# LM3S6965 register map
Vendor: Texas Instruments; File version: 1.0
Stellaris LM3S6965, подмножество: SYSCTL, GPIOA–GPIOG, UART0, UART1, TIMER0–TIMER3, ADC0
CPU: CM3 r2p0, little endian, MPU, no FPU, 3 interrupt priority bits
Registers are 32-bit, read-write, reset 0x0 unless marked. A register's access mark holds for its fields unless they carry their own. Offsets are from the block's base; lines under a group give offsets from that group; [hi:lo] are bit positions; {n}, {i} and the like mark numbered series; 'fields as' and 'values as' point back to an identical list; <NAME> marks a mode.

## Memory map
0x40004000 GPIOA size 0x1000 — Порт ввода-вывода общего назначения (PL061)
0x40005000 GPIOB size 0x1000
0x40006000 GPIOC size 0x1000
0x40007000 GPIOD size 0x1000
0x4000C000 UART0 size 0x1000 — Универсальный асинхронный приёмопередатчик (PL011)
0x4000D000 UART1 size 0x1000
0x40024000 GPIOE size 0x1000
0x40025000 GPIOF size 0x1000
0x40026000 GPIOG size 0x1000
0x40030000 TIMER0 size 0x1000 — Таймер общего назначения (GPTM)
0x40031000 TIMER1 size 0x1000
0x40032000 TIMER2 size 0x1000
0x40033000 TIMER3 size 0x1000
0x40038000 ADC0 size 0x1000 — Аналого-цифровой преобразователь, 10 бит
0x400FE000 SYSCTL size 0x1000 — Системное управление: тактирование и сброс

## Interrupts
0 GPIOA
1 GPIOB
2 GPIOC
3 GPIOD
4 GPIOE
5 UART0
6 UART1
14 ADC0SS0 (ADC0)
15 ADC0SS1 (ADC0)
16 ADC0SS2 (ADC0)
17 ADC0SS3 (ADC0)
19 TIMER0A (TIMER0)
20 TIMER0B (TIMER0)
21 TIMER1A (TIMER1)
22 TIMER1B (TIMER1)
23 TIMER2A (TIMER2)
24 TIMER2B (TIMER2)
30 GPIOF
31 GPIOG
35 TIMER3A (TIMER3)
36 TIMER3B (TIMER3)

## SYSCTL — Системное управление: тактирование и сброс
Base 0x400FE000
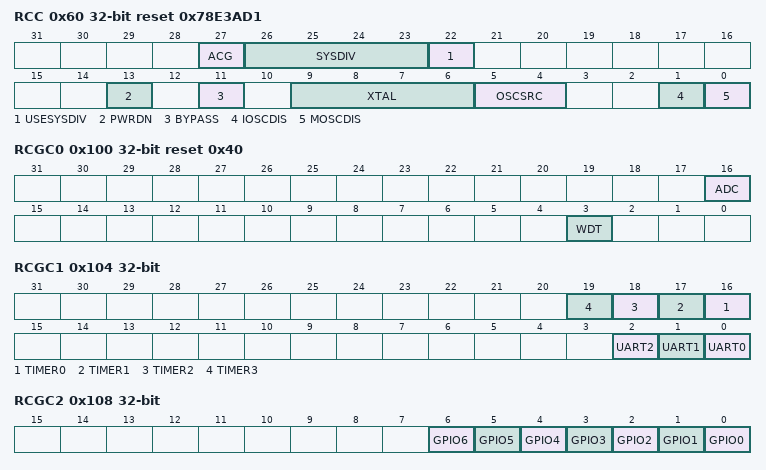
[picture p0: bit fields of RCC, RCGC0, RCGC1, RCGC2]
0x60 RCC reset 0x78E3AD1 — Настройка тактирования
  [27] ACG — Автоматическое управление тактами в режимах сна
  [26:23] SYSDIV — Делитель системной частоты
  [22] USESYSDIV — Делить системную частоту на SYSDIV + 1
  [13] PWRDN — Выключить PLL
  [11] BYPASS — Обойти PLL
  [9:6] XTAL — Частота кварца
  [5:4] OSCSRC — Источник тактов
    0=MAIN (Главный генератор); 1=INTERNAL (Внутренний генератор 12 МГц); 2=INTERNAL_DIV4 (Внутренний генератор, делённый на 4)
  [1] IOSCDIS — Выключить внутренний генератор
  [0] MOSCDIS — Выключить главный генератор
0x100 RCGC0 reset 0x40 — Такты периферии в рабочем режиме, группа 0
  [16] ADC — АЦП
  [3] WDT — Сторожевой таймер
0x104 RCGC1 — Такты периферии в рабочем режиме, группа 1
  [n+16] TIMER{n} (n=0..3) — Таймеры 0–3
  [n] UART{n} (n=0..2) — UART0–UART2
0x108 RCGC2 — Такты периферии в рабочем режиме, группа 2: порты GPIO
  [n] GPIO{n} (n=0..6) — Порты A–G (бит 0 — порт A)

## GPIOA — Порт ввода-вывода общего назначения (PL061)
Base 0x40004000
Same registers: GPIOB 0x40005000, GPIOC 0x40006000, GPIOD 0x40007000, GPIOE 0x40024000, GPIOF 0x40025000, GPIOG 0x40026000
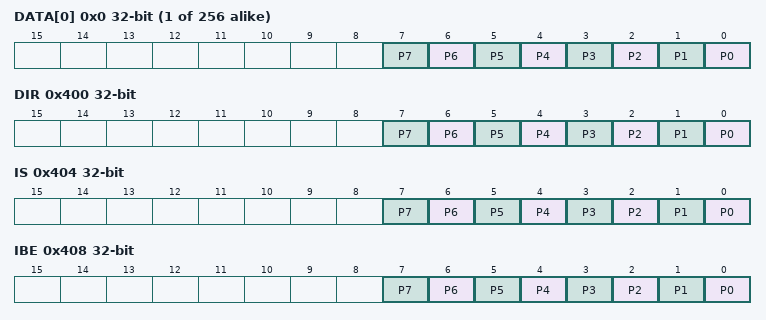
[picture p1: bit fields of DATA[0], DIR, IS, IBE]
{0x0+4i} DATA[{i}] (i=0..255) — Данные. Биты 2–9 адреса — маска: читаются и пишутся только выводы, чьи биты маски равны 1
  [n] P{n} (n=0..7) — Уровень вывода
0x400 DIR — Направление: 1 — выход
  [n] P{n} (n=0..7) — Вывод — выход
0x404 IS — Чувствительность прерывания: 1 — по уровню, 0 — по фронту
  [n] P{n} (n=0..7) — По уровню
0x408 IBE — Прерывание по обоим фронтам
  [n] P{n} (n=0..7) — Оба фронта
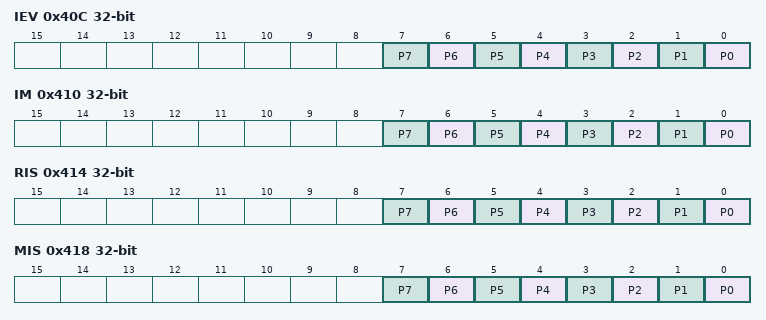
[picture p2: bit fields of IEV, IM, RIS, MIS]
0x40C IEV — Событие прерывания: 1 — нарастающий фронт или высокий уровень
  [n] P{n} (n=0..7) — Нарастающий фронт или высокий уровень
0x410 IM — Маска прерываний: 1 — прерывание разрешено
  [n] P{n} (n=0..7) — Прерывание разрешено
0x414 RIS ro — Необработанные запросы прерываний
  [n] P{n} (n=0..7) — Запрос есть
0x418 MIS ro — Запросы прерываний после маски
  [n] P{n} (n=0..7) — Запрос есть
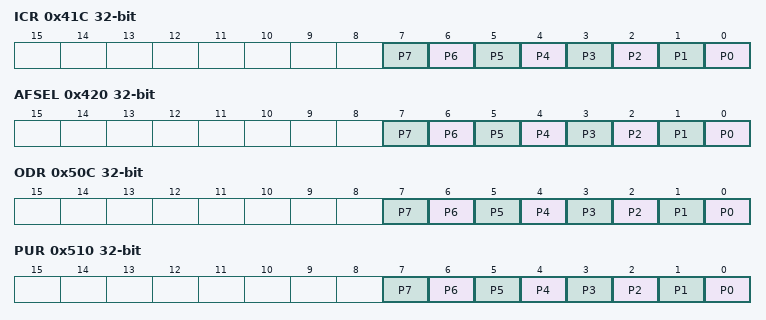
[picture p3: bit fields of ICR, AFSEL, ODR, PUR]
0x41C ICR wo — Сброс запросов прерываний по фронту: 1 сбрасывает бит
  [n] P{n} (n=0..7) — Сбросить запрос
0x420 AFSEL — Альтернативная функция: 1 — выводом управляет периферия
  [n] P{n} (n=0..7) — Альтернативная функция
0x50C ODR — Открытый сток
  [n] P{n} (n=0..7)
0x510 PUR — Подтяжка к питанию
  [n] P{n} (n=0..7)
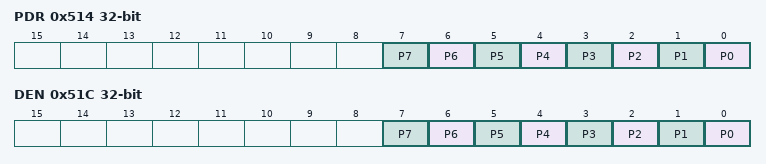
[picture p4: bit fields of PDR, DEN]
0x514 PDR — Подтяжка к земле
  [n] P{n} (n=0..7)
0x51C DEN — Цифровой режим: 1 — вывод работает как цифровой
  [n] P{n} (n=0..7) — Цифровой режим
